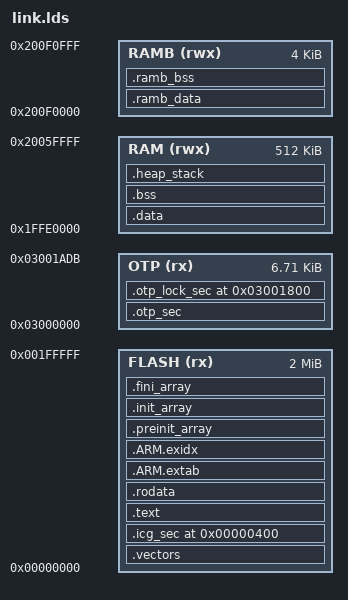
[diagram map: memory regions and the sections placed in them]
 /**
  *******************************************************************************
 * @file  hc32f4a0_flash.lds
 * @brief Linker script for HC32F4A0 Device with 2MByte FLASH, 512KByte RAM.
 @verbatim
   Change Logs:
   Date             Author          Notes
   2020-09-15       Chengy            First version
 @endverbatim
 *******************************************************************************
 * Copyright (C) 2020, Huada Semiconductor Co., Ltd. All rights reserved.
 *
 * This software component is licensed by HDSC under BSD 3-Clause license
 * (the "License"); You may not use this file except in compliance with the
 * License. You may obtain a copy of the License at:
 *                    opensource.org/licenses/BSD-3-Clause
 *
 *******************************************************************************
 */

/* Use contiguous memory regions for simple. */
MEMORY
{
    FLASH       (rx): ORIGIN = 0x00000000, LENGTH = 2M
    OTP         (rx): ORIGIN = 0x03000000, LENGTH = 6876
    RAM        (rwx): ORIGIN = 0x1FFE0000, LENGTH = 512K
    RAMB       (rwx): ORIGIN = 0x200F0000, LENGTH = 4K
}

ENTRY(Reset_Handler)

SECTIONS
{
    .vectors :
    {
        . = ALIGN(4);
        KEEP(*(.vectors))
        . = ALIGN(4);
    } >FLASH

    .icg_sec 0x00000400 :
    {
        KEEP(*(.icg_sec))
    } >FLASH

    .text :
    {
        . = ALIGN(4);
        *(.text)
        *(.text*)
        *(.glue_7)
        *(.glue_7t)
        *(.eh_frame)

        KEEP(*(.init))
        KEEP(*(.fini))
        . = ALIGN(4);
    } >FLASH

    .rodata :
    {
        . = ALIGN(4);
        *(.rodata)
        *(.rodata*)
        . = ALIGN(4);
    } >FLASH

    .ARM.extab :
    {
        *(.ARM.extab* .gnu.linkonce.armextab.*)
    } >FLASH

    __exidx_start = .;
    .ARM.exidx :
    {
        *(.ARM.exidx* .gnu.linkonce.armexidx.*)
    } >FLASH
    __exidx_end = .;

    .preinit_array :
    {
        . = ALIGN(4);
        /* preinit data */
        PROVIDE_HIDDEN (__preinit_array_start = .);
        KEEP(*(.preinit_array))
        PROVIDE_HIDDEN (__preinit_array_end = .);
        . = ALIGN(4);
    } >FLASH

    .init_array :
    {
        . = ALIGN(4);
        /* init data */
        PROVIDE_HIDDEN (__init_array_start = .);
        KEEP(*(SORT(.init_array.*)))
        KEEP(*(.init_array))
        PROVIDE_HIDDEN (__init_array_end = .);
        . = ALIGN(4);
    } >FLASH

    .fini_array :
    {
        . = ALIGN(4);
        /* finit data */
        PROVIDE_HIDDEN (__fini_array_start = .);
        KEEP(*(SORT(.fini_array.*)))
        KEEP(*(.fini_array))
        PROVIDE_HIDDEN (__fini_array_end = .);
        . = ALIGN(4);
    } >FLASH

    __etext = ALIGN(4);

    .otp_sec :
    {
        KEEP(*(.otp_sec))
    } >OTP

    .otp_lock_sec 0x03001800 :
    {
        KEEP(*(.otp_lock_sec))
    } >OTP

    .data : AT (__etext)
    {
        . = ALIGN(4);
        __data_start__ = .;
        *(vtable)
        *(.data)
        *(.data*)
        . = ALIGN(4);
        *(.ramfunc)
        *(.ramfunc*)
        . = ALIGN(4);
        __data_end__ = .;
    } >RAM

    __etext_ramb = __etext + ALIGN (SIZEOF(.data), 4);
    .ramb_data : AT (__etext_ramb)
    {
        . = ALIGN(4);
        __data_start_ramb__ = .;
        *(.ramb_data)
        *(.ramb_data*)
        . = ALIGN(4);
        __data_end_ramb__ = .;
    } >RAMB

    .bss :
    {
        . = ALIGN(4);
        _sbss = .;
        __bss_start__ = _sbss;
        *(.bss)
        *(.bss*)
        *(COMMON)
        . = ALIGN(4);
        _ebss = .;
        __bss_end__ = _ebss;
    } >RAM

    .ramb_bss :
    {
        . = ALIGN(4);
        __bss_start_ramb__ = .;
        *(.ramb_bss)
        *(.ramb_bss*)
        . = ALIGN(4);
        __bss_end_ramb__ = .;
    } >RAMB

    .heap_stack (COPY) :
    {
        . = ALIGN(8);
        __end__ = .;
        PROVIDE(end = .);
        PROVIDE(_end = .);
        *(.heap*)
        . = ALIGN(8);
        __HeapLimit = .;

        __StackLimit = .;
        *(.stack*)
        . = ALIGN(8);
        __StackTop = .;
    } >RAM

    /DISCARD/ :
    {
        libc.a (*)
        libm.a (*)
        libgcc.a (*)
    }

    .ARM.attributes 0 : { *(.ARM.attributes) }

    PROVIDE(_stack = __StackTop);
    PROVIDE(_Min_Heap_Size = __HeapLimit - __HeapBase);
    PROVIDE(_Min_Stack_Size = __StackTop - __StackLimit);

    __RamEnd = ORIGIN(RAM) + LENGTH(RAM);
    ASSERT(__StackTop <= __RamEnd, "region RAM overflowed with stack")
}
